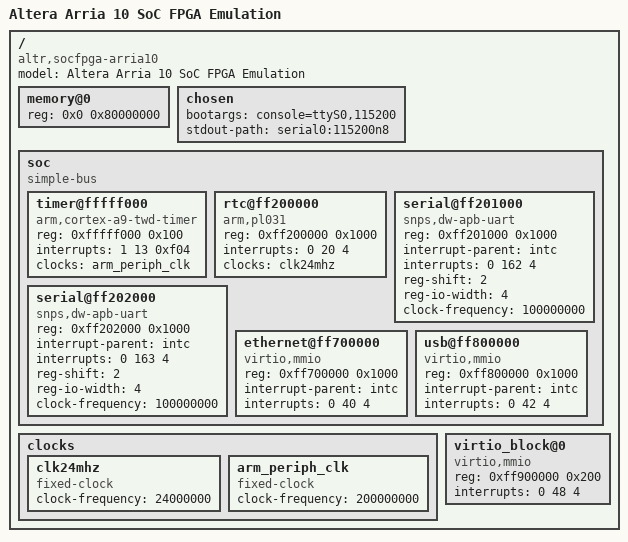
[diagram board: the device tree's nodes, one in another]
/*
 * Device Tree for Arria 10 SoC FPGA Emulation
 */

/dts-v1/;

/ {
	model = "Altera Arria 10 SoC FPGA Emulation";
	compatible = "altr,socfpga-arria10", "altr,socfpga";
	
	#address-cells = <1>;
	#size-cells = <1>;
	
	/* User configurable memory, default to 2GB */
	memory@0 {
		device_type = "memory";
		reg = <0x0 0x80000000>; /* 2GB */
		/* Can be configured up to 3GB for ARMv7-A */
	};
	
	chosen {
		bootargs = "console=ttyS0,115200";
		stdout-path = "serial0:115200n8";
	};
	
	soc {
		#address-cells = <1>;
		#size-cells = <1>;
		compatible = "simple-bus";
		ranges;
		
		timer@fffff000 {
			compatible = "arm,cortex-a9-twd-timer";
			reg = <0xfffff000 0x100>;
			interrupts = <1 13 0xf04>;
			clocks = <&arm_periph_clk>;
		};
		
		/* RTC Driver */
		rtc@ff200000 {
			compatible = "arm,pl031", "arm,primecell";
			reg = <0xff200000 0x1000>;
			interrupts = <0 20 4>;
			clocks = <&clk24mhz>;
			clock-names = "apb_pclk";
		};
		
		/* 2x Virtual IO Console (Serial Interface) */
		serial@ff201000 {
			compatible = "snps,dw-apb-uart";
			reg = <0xff201000 0x1000>;
			interrupt-parent = <&intc>;
			interrupts = <0 162 4>;
			reg-shift = <2>;
			reg-io-width = <4>;
			clock-frequency = <100000000>;
			status = "okay";
		};
		
		serial@ff202000 {
			compatible = "snps,dw-apb-uart";
			reg = <0xff202000 0x1000>;
			interrupt-parent = <&intc>;
			interrupts = <0 163 4>;
			reg-shift = <2>;
			reg-io-width = <4>;
			clock-frequency = <100000000>;
			status = "okay";
		};
		
		/* 1x Virtual IO Ethernet device */
		ethernet@ff700000 {
			compatible = "virtio,mmio";
			reg = <0xff700000 0x1000>;
			interrupt-parent = <&intc>;
			interrupts = <0 40 4>;
			status = "okay";
		};
		
		/* 1x Virtual IO USB Host interface */
		usb@ff800000 {
			compatible = "virtio,mmio";
			reg = <0xff800000 0x1000>;
			interrupt-parent = <&intc>;
			interrupts = <0 42 4>;
			status = "okay";
		};
	};
	
	clocks {
		clk24mhz: clk24mhz {
			#clock-cells = <0>;
			compatible = "fixed-clock";
			clock-frequency = <24000000>;
		};
		
		arm_periph_clk: arm_periph_clk {
			#clock-cells = <0>;
			compatible = "fixed-clock";
			clock-frequency = <200000000>;
		};
	};
	
	virtio_block@0 {
		compatible = "virtio,mmio";
		reg = <0xff900000 0x200>;
		interrupts = <0 48 4>;
	};
};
